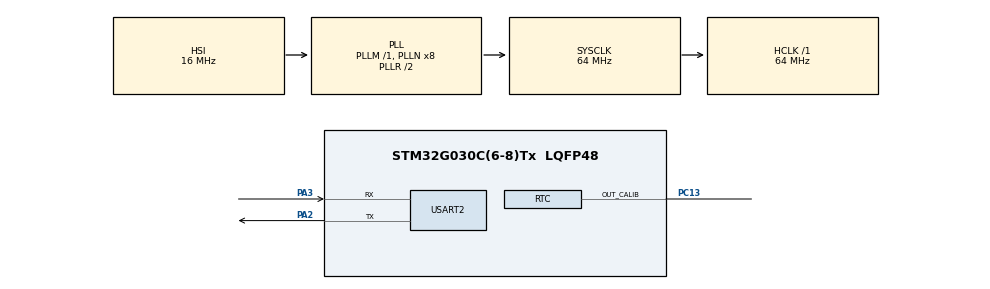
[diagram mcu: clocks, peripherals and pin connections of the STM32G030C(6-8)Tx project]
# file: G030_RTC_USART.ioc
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Mcu.Family=STM32G0
Mcu.Name=STM32G030C(6-8)Tx
Mcu.Package=LQFP48
NVIC.USART2_IRQn=true\:0\:0\:false\:false\:true\:true\:true
PA13.Mode=Serial_Wire
PA13.Signal=SYS_SWDIO
PA14-BOOT0.Mode=Serial_Wire
PA14-BOOT0.Signal=SYS_SWCLK
PA2.Mode=Asynchronous
PA2.Signal=USART2_TX
PA3.Mode=Asynchronous
PA3.Signal=USART2_RX
PC13.Mode=Calibration_512Hz
PC13.Signal=RTC_OUT_CALIB
PC14-OSC32_IN\ (PC14).Mode=LSE-External-Oscillator
PC14-OSC32_IN\ (PC14).Signal=RCC_OSC32_IN
PC15-OSC32_OUT\ (PC15).Mode=LSE-External-Oscillator
PC15-OSC32_OUT\ (PC15).Signal=RCC_OSC32_OUT
ProjectManager.HeapSize=0x200
ProjectManager.StackSize=0x400
ProjectManager.TargetToolchain=STM32CubeIDE
RCC.ADCFreq_Value=64000000
RCC.AHBFreq_Value=64000000
RCC.CortexFreq_Value=64000000
RCC.EXTERNAL_CLOCK_VALUE=12288000
RCC.HCLKFreq_Value=64000000
RCC.HSE_VALUE=8000000
RCC.HSI_VALUE=16000000
RCC.RTCClockSelection=RCC_RTCCLKSOURCE_LSE
RCC.SYSCLKFreq_VALUE=64000000
RCC.SYSCLKSource=RCC_SYSCLKSOURCE_PLLCLK
RCC.VCOOutputFreq_Value=128000000
USART2.VirtualMode-Asynchronous=VM_ASYNC
VP_RTC_VS_RTC_Activate.Mode=RTC_Enabled
board=custom

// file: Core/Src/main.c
/* USER CODE BEGIN Header */
/**
  ******************************************************************************
  * @file           : main.c
  * @brief          : Main program body
  ******************************************************************************
  * @attention
  *
  * <h2><center>&copy; Copyright (c) 2021 STMicroelectronics.
  * All rights reserved.</center></h2>
  *
  * This software component is licensed by ST under BSD 3-Clause license,
  * the "License"; You may not use this file except in compliance with the
  * License. You may obtain a copy of the License at:
  *                        opensource.org/licenses/BSD-3-Clause
  *
  ******************************************************************************
  */
/* USER CODE END Header */
#include "main.h"
#include "rtc.h"
#include "usart.h"
#include "gpio.h"

/* USER CODE BEGIN Includes */
#include "string.h"
#include "stdio.h"
#include "uart_debug.h"
#include "shell_port.h"

/* USER CODE END Includes */

/* USER CODE BEGIN PV */
uint8_t uartRxData[1] = {0};

/* USER CODE END PV */

void SystemClock_Config(void);
/* USER CODE BEGIN PFP */
/************************************函数注册方法示例***********************************/
int test(int i, char ch, char *str)
{
    printf("input int: %d, char: %c, string: %s\r\n", i, ch, str);

  return 0;
}
//导出到命令列表里
SHELL_EXPORT_CMD(SHELL_CMD_PERMISSION(0)|SHELL_CMD_TYPE(SHELL_TYPE_CMD_FUNC), test, test, test);

int func(int argc, char *agrv[])
{
    printf("%d parameter(s)\r\n", argc);
    for (int i = 1; i < argc; i++)
    {
        printf("%s\r\n", agrv[i]);
    }

    return 0;
}
SHELL_EXPORT_CMD(SHELL_CMD_PERMISSION(0)|SHELL_CMD_TYPE(SHELL_TYPE_CMD_MAIN), func, func, test);

/* USER CODE END PFP */

int main(void)
{

  /* MCU Configuration--------------------------------------------------------*/

  /* Reset of all peripherals, Initializes the Flash interface and the Systick. */
  HAL_Init();

  /* Configure the system clock */
  SystemClock_Config();

  /* Initialize all configured peripherals */
  MX_GPIO_Init();
  MX_RTC_Init();
  MX_USART2_UART_Init();
  /* USER CODE BEGIN 2 */
  HAL_UART_Receive_IT(&huart2, uartRxData, sizeof(uartRxData));
  User_Shell_Init();

  /* USER CODE END 2 */

  /* Infinite loop */
  /* USER CODE BEGIN WHILE */
  while (1)
  {
//    shellTask(&shell);
	  printf("hello.");
//    HAL_UART_Transmit(&huart1, "1\r\n", 2, 200);
    /* USER CODE END WHILE */

  }
}

void SystemClock_Config(void)
{
  RCC_OscInitTypeDef RCC_OscInitStruct = {0};
  RCC_ClkInitTypeDef RCC_ClkInitStruct = {0};
  RCC_PeriphCLKInitTypeDef PeriphClkInit = {0};

  /** Configure the main internal regulator output voltage
  */
  HAL_PWREx_ControlVoltageScaling(PWR_REGULATOR_VOLTAGE_SCALE1);
  /** Configure LSE Drive Capability
  */
  HAL_PWR_EnableBkUpAccess();
  __HAL_RCC_LSEDRIVE_CONFIG(RCC_LSEDRIVE_LOW);
  /** Initializes the RCC Oscillators according to the specified parameters
  * in the RCC_OscInitTypeDef structure.
  */
  RCC_OscInitStruct.OscillatorType = RCC_OSCILLATORTYPE_HSI|RCC_OSCILLATORTYPE_LSE;
  RCC_OscInitStruct.LSEState = RCC_LSE_ON;
  RCC_OscInitStruct.HSIState = RCC_HSI_ON;
  RCC_OscInitStruct.HSIDiv = RCC_HSI_DIV1;
  RCC_OscInitStruct.HSICalibrationValue = RCC_HSICALIBRATION_DEFAULT;
  RCC_OscInitStruct.PLL.PLLState = RCC_PLL_ON;
  RCC_OscInitStruct.PLL.PLLSource = RCC_PLLSOURCE_HSI;
  RCC_OscInitStruct.PLL.PLLM = RCC_PLLM_DIV1;
  RCC_OscInitStruct.PLL.PLLN = 8;
  RCC_OscInitStruct.PLL.PLLP = RCC_PLLP_DIV2;
  RCC_OscInitStruct.PLL.PLLR = RCC_PLLR_DIV2;
  if (HAL_RCC_OscConfig(&RCC_OscInitStruct) != HAL_OK)
  {
    Error_Handler();
  }
  /** Initializes the CPU, AHB and APB buses clocks
  */
  RCC_ClkInitStruct.ClockType = RCC_CLOCKTYPE_HCLK|RCC_CLOCKTYPE_SYSCLK
                              |RCC_CLOCKTYPE_PCLK1;
  RCC_ClkInitStruct.SYSCLKSource = RCC_SYSCLKSOURCE_PLLCLK;
  RCC_ClkInitStruct.AHBCLKDivider = RCC_SYSCLK_DIV1;
  RCC_ClkInitStruct.APB1CLKDivider = RCC_HCLK_DIV1;

  if (HAL_RCC_ClockConfig(&RCC_ClkInitStruct, FLASH_LATENCY_2) != HAL_OK)
  {
    Error_Handler();
  }
  /** Initializes the peripherals clocks
  */
  PeriphClkInit.PeriphClockSelection = RCC_PERIPHCLK_RTC;
  PeriphClkInit.RTCClockSelection = RCC_RTCCLKSOURCE_LSE;

  if (HAL_RCCEx_PeriphCLKConfig(&PeriphClkInit) != HAL_OK)
  {
    Error_Handler();
  }
}

/* USER CODE BEGIN 4 */
/**
  * @brief  Rx Transfer completed callback.
  * @param  huart UART handle.
  * @retval None
  */
void HAL_UART_RxCpltCallback(UART_HandleTypeDef *huart)
{
  if (USART2 == huart->Instance)
  {
    shellHandler(&shell, uartRxData[0]);
    HAL_UART_Receive_IT(&huart2, uartRxData, sizeof(uartRxData));
  }
}
/* USER CODE END 4 */

void Error_Handler(void)
{
  __disable_irq();
  while (1)
  {
  }
}

/************************ (C) COPYRIGHT STMicroelectronics *****END OF FILE****/
